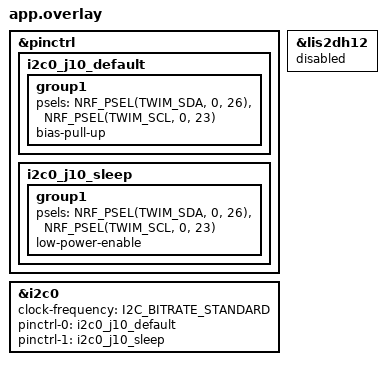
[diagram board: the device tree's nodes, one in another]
#include <zephyr/dt-bindings/i2c/i2c.h>
#include <zephyr/dt-bindings/pinctrl/nrf-pinctrl.h>

&pinctrl {
	i2c0_j10_default: i2c0_j10_default {
		group1 {
			psels = <NRF_PSEL(TWIM_SDA, 0, 26)>,
				<NRF_PSEL(TWIM_SCL, 0, 23)>;
			bias-pull-up;
		};
	};

	i2c0_j10_sleep: i2c0_j10_sleep {
		group1 {
			psels = <NRF_PSEL(TWIM_SDA, 0, 26)>,
				<NRF_PSEL(TWIM_SCL, 0, 23)>;
			low-power-enable;
		};
	};
};

&lis2dh12 {
	status = "disabled";
};

&i2c0 {
	status = "okay";
	clock-frequency = <I2C_BITRATE_STANDARD>;
	pinctrl-0 = <&i2c0_j10_default>;
	pinctrl-1 = <&i2c0_j10_sleep>;
	pinctrl-names = "default", "sleep";
};
